# WLR089U0 register map
Vendor: Microchip
Registers are 32-bit, read-write, reset 0x0 unless marked. A register's access mark holds for its fields unless they carry their own. Addresses are absolute, and some are shared; only a register's first bit layout is shown; [hi:lo] are bit positions; {n}, {i} and the like mark numbered series; 'fields as' and 'values as' point back to an identical list.

## PAC
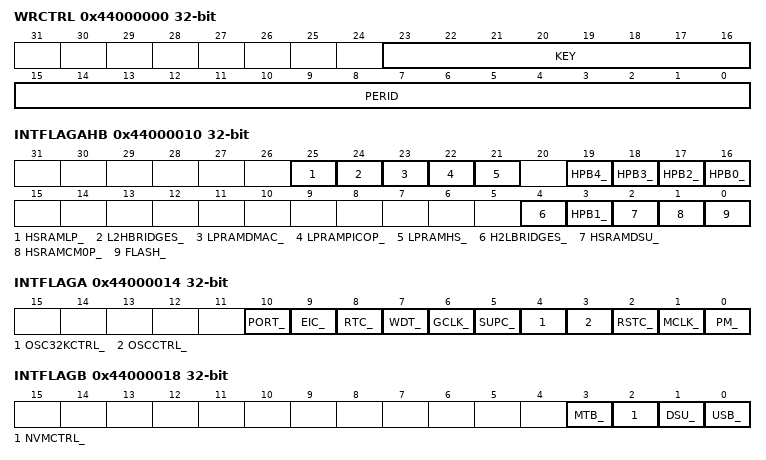
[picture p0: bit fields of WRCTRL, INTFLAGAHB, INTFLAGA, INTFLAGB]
0x44000000 WRCTRL
  [23:16] KEY — Peripheral access control key
    0=OFF (No action); 1=CLR (Clear protection); 2=SET (Set protection); 3=SETLCK (Set and lock protection)
  [15:0] PERID — Peripheral identifier
0x44000004 EVCTRL 8-bit
  [0] ERREO — Peripheral acess error event output
0x44000008 INTENCLR 8-bit
  [0] ERR — Peripheral access error interrupt disable
0x44000009 INTENSET 8-bit
  [0] ERR — Peripheral access error interrupt enable
0x44000010 INTFLAGAHB
  [25] HSRAMLP_, [24] L2HBRIDGES_, [23] LPRAMDMAC_, [22] LPRAMPICOP_, [21] LPRAMHS_, [19] HPB4_, [18] HPB3_, [17] HPB2_, [16] HPB0_, [4] H2LBRIDGES_, [3] HPB1_, [2] HSRAMDSU_, [1] HSRAMCM0P_, [0] FLASH_
0x44000014 INTFLAGA
  [10] PORT_, [9] EIC_, [8] RTC_, [7] WDT_, [6] GCLK_, [5] SUPC_, [4] OSC32KCTRL_, [3] OSCCTRL_, [2] RSTC_, [1] MCLK_, [0] PM_
0x44000018 INTFLAGB
  [3] MTB_, [2] NVMCTRL_, [1] DSU_, [0] USB_
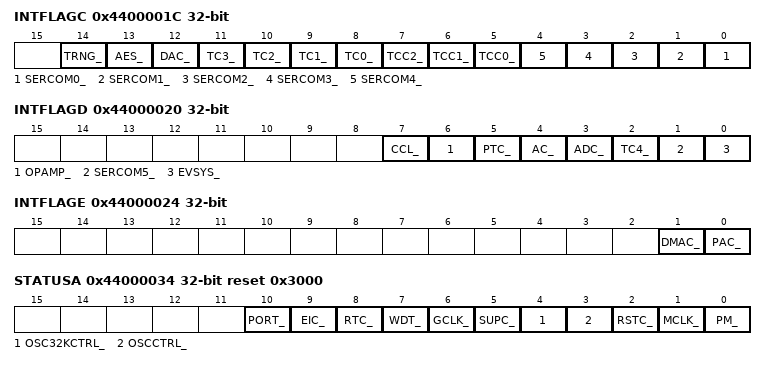
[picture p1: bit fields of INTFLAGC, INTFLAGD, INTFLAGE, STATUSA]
0x4400001C INTFLAGC
  [14] TRNG_, [13] AES_, [12] DAC_, [n+8] TC{n}_ (n=0..3), [7] TCC2_, [6] TCC1_, [5] TCC0_, [n] SERCOM{n}_ (n=0..4)
0x44000020 INTFLAGD
  [7] CCL_, [6] OPAMP_, [5] PTC_, [4] AC_, [3] ADC_, [2] TC4_, [1] SERCOM5_, [0] EVSYS_
0x44000024 INTFLAGE
  [1] DMAC_, [0] PAC_
0x44000034 STATUSA ro reset 0x3000
  [10] PORT_ — PORT APB Protect Enable
  [9] EIC_ — EIC APB Protect Enable
  [8] RTC_ — RTC APB Protect Enable
  [7] WDT_ — WDT APB Protect Enable
  [6] GCLK_ — GCLK APB Protect Enable
  [5] SUPC_ — SUPC APB Protect Enable
  [4] OSC32KCTRL_ — OSC32KCTRL APB Protect Enable
  [3] OSCCTRL_ — OSCCTRL APB Protect Enable
  [2] RSTC_ — RSTC APB Protect Enable
  [1] MCLK_ — MCLK APB Protect Enable
  [0] PM_ — PM APB Protect Enable
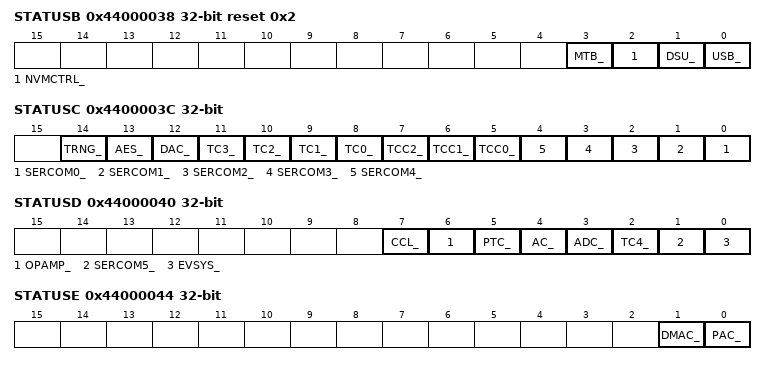
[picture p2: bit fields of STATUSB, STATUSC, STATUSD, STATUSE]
0x44000038 STATUSB ro reset 0x2
  [3] MTB_ — MTB APB Protect Enable
  [2] NVMCTRL_ — NVMCTRL APB Protect Enable
  [1] DSU_ — DSU APB Protect Enable
  [0] USB_ — USB APB Protect Enable
0x4400003C STATUSC ro
  [14] TRNG_ — TRNG APB Protect Enable
  [13] AES_ — AES APB Protect Enable
  [12] DAC_ — DAC APB Protect Enable
  [n+8] TC{n}_ (n=0..3) — TC{n} APB Protect Enable
  [7] TCC2_ — TCC2 APB Protect Enable
  [6] TCC1_ — TCC1 APB Protect Enable
  [5] TCC0_ — TCC0 APB Protect Enable
  [n] SERCOM{n}_ (n=0..4) — SERCOM{n} APB Protect Enable
0x44000040 STATUSD ro
  [7] CCL_ — CCL APB Protect Enable
  [6] OPAMP_ — OPAMP APB Protect Enable
  [5] PTC_ — PTC APB Protect Enable
  [4] AC_ — AC APB Protect Enable
  [3] ADC_ — ADC APB Protect Enable
  [2] TC4_ — TC4 APB Protect Enable
  [1] SERCOM5_ — SERCOM5 APB Protect Enable
  [0] EVSYS_ — EVSYS APB Protect Enable
0x44000044 STATUSE ro
  [1] DMAC_ — DMAC APB Protect Enable
  [0] PAC_ — PAC APB Protect Enable

## CONFIG — Configuration words, addresses in FusesSpace
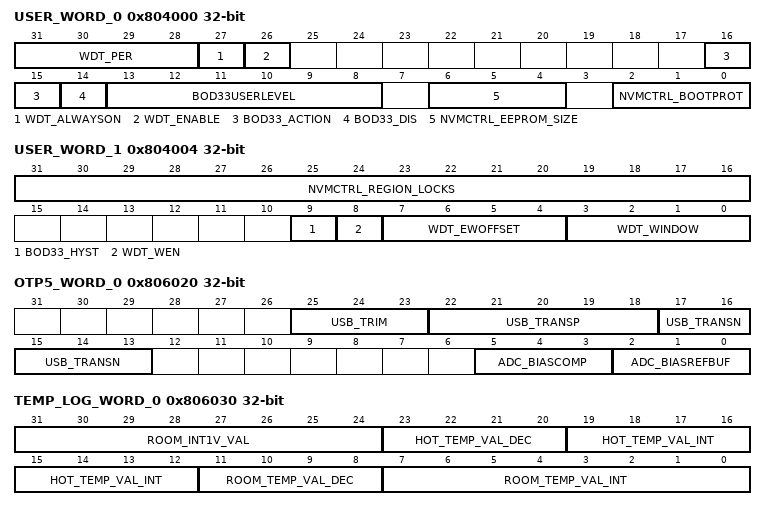
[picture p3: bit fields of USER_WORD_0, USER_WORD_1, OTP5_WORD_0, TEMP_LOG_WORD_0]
0x804000 USER_WORD_0
  [31:28] WDT_PER — WDT Period
    0=CYC8 (8 clock cycles); 1=CYC16 (16 clock cycles); 2=CYC32 (32 clock cycles); 3=CYC64 (64 clock cycles); 4=CYC128 (128 clock cycles); 5=CYC256 (256 clock cycles); 6=CYC512 (512 clock cycles); 7=CYC1024 (1024 clock cycles); 8=CYC2048 (2048 clock cycles); 9=CYC4096 (4096 clock cycles); 10=CYC8192 (8192 clock cycles); 11=CYC16384 (16384 clock cycles)
  [27] WDT_ALWAYSON
    1=SET; 0=CLEAR
  [26] WDT_ENABLE
    1=SET; 0=CLEAR
  [16:15] BOD33_ACTION
    0=NONE (No action); 1=RESET (The BOD33 generates a reset); 2=INT (The BOD33 generates an interrupt); 3=BKUP (The BOD33 puts the device in backup sleep mode)
  [14] BOD33_DIS — BOD33 Disable
    1=SET; 0=CLEAR
  [13:8] BOD33USERLEVEL
  [6:4] NVMCTRL_EEPROM_SIZE — EEPROM Size
    7=SIZE_0BYTES (0 Bytes); 6=SIZE_256BYTES (256 Bytes); 5=SIZE_512BYTES (512 Bytes); 4=SIZE_1024BYTES (1024 Bytes); 3=SIZE_2048BYTES (2048 Bytes); 2=SIZE_4096BYTES (4096 Bytes); 1=SIZE_8192BYTES (8192 Bytes); 0=SIZE_16384BYTES (16384 Bytes)
  [2:0] NVMCTRL_BOOTPROT — Bootloader Size
    7=SIZE_0BYTES (0 Bytes); 6=SIZE_512BYTES (512 Bytes); 5=SIZE_1024BYTES (1024 Bytes); 4=SIZE_2048BYTES (2048 Bytes); 3=SIZE_4096BYTES (4096 Bytes); 2=SIZE_8192BYTES (8192 Bytes); 1=SIZE_16384BYTES (16384 Bytes); 0=SIZE_32768BYTES (32768 Bytes)
0x804004 USER_WORD_1
  [31:16] NVMCTRL_REGION_LOCKS — NVM Region Locks
  [9] BOD33_HYST — BOD33 Hysteresis
    1=SET; 0=CLEAR
  [8] WDT_WEN — WDT Window Mode Enable
    1=SET; 0=CLEAR
  [7:4] WDT_EWOFFSET — WDT Early Warning Offset
    values as USER_WORD_0.WDT_PER
  [3:0] WDT_WINDOW
    values as USER_WORD_0.WDT_PER
0x806020 OTP5_WORD_0 ro
  [25:23] USB_TRIM — USB pad Trim calibration
  [22:18] USB_TRANSP — USB pad Transp calibration
  [17:13] USB_TRANSN — USB pad Transn calibration
  [5:3] ADC_BIASCOMP — ADC Comparator Scaling
  [2:0] ADC_BIASREFBUF — ADC Bias Reference Buffer Scaling
0x806030 TEMP_LOG_WORD_0 ro
  [31:24] ROOM_INT1V_VAL — 2's complement of the internal 1V reference drift at room temperature (versus a 1.0 centered value)
  [23:20] HOT_TEMP_VAL_DEC — Decimal part of hot temperature
  [19:12] HOT_TEMP_VAL_INT — Integer part of hot temperature in oC
  [11:8] ROOM_TEMP_VAL_DEC — Decimal part of room temperature
  [7:0] ROOM_TEMP_VAL_INT — Integer part of room temperature in oC
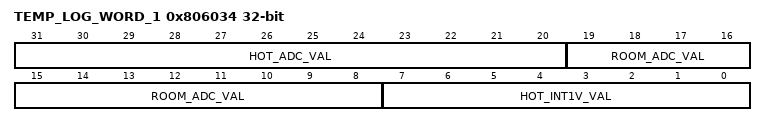
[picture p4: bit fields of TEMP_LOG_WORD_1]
0x806034 TEMP_LOG_WORD_1 ro
  [31:20] HOT_ADC_VAL — 12-bit ADC conversion at hot temperature
  [19:8] ROOM_ADC_VAL — 12-bit ADC conversion at room temperature
  [7:0] HOT_INT1V_VAL — 2's complement of the internal 1V reference drift at hot temperature (versus a 1.0 centered value)
